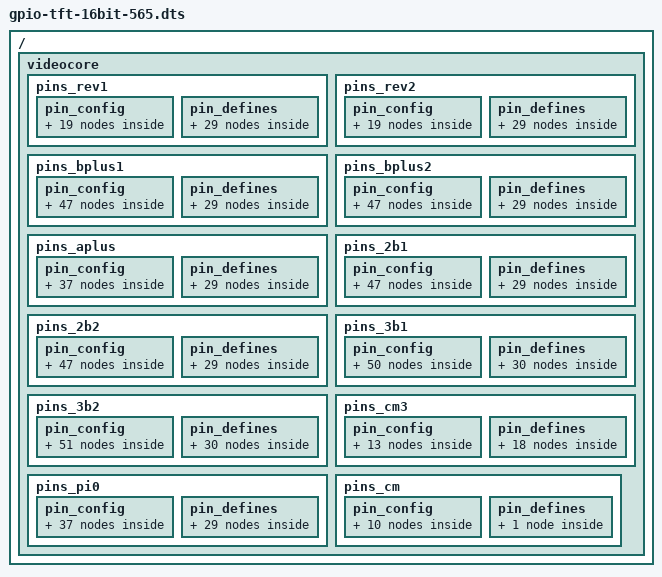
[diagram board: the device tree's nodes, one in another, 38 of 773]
/dts-v1/;

// Compile with the following script:
//#! /bin/bash
//echo "sudo dtc -I dts -O dtb -o /boot/dt-blob.bin gpio-tft-16bit-565.dts"
//sudo dtc -I dts -O dtb -o /boot/dt-blob.bin gpio-tft-16bit-565.dts


/ {
   videocore {
      pins_rev1 {
         pin_config {
            pin@default {
               polarity = "active_high";
               termination = "pull_down";
               startup_state = "inactive";
               function = "input";
            }; // pin
            pin@p2  { function = "i2c1";   termination = "pull_up"; }; // I2C 1 SDA
            pin@p3  { function = "i2c1";   termination = "pull_up"; }; // I2C 1 SCL
            pin@p5  { function = "output"; termination = "pull_down"; }; // CAM_LED
            pin@p6  { function = "output"; termination = "pull_down"; }; // LAN NRESET
            pin@p14 { function = "uart0";  termination = "no_pulling"; drive_strength_mA = < 8 >; }; // TX uart0
            pin@p15 { function = "uart0";  termination = "pull_up"; drive_strength_mA = < 8 >; }; // RX uart0
            pin@p16 { function = "output"; termination = "pull_up"; polarity="active_low"; }; // activity LED
            pin@p27 { function = "output"; termination = "no_pulling";    }; // Camera shutdown
            pin@p40 { function = "pwm";    termination = "no_pulling"; drive_strength_mA = < 16 >; }; // Left audio
            pin@p45 { function = "pwm";    termination = "no_pulling"; drive_strength_mA = < 16 >; }; // Right audio
            pin@p46 { function = "input";  termination = "no_pulling";    }; // Hotplug
            pin@p47 { function = "input";  termination = "no_pulling";    }; // SD_CARD_DETECT
            pin@p48 { function = "sdcard"; termination = "pull_up";    drive_strength_mA = < 8 >; }; // SD CLK
            pin@p49 { function = "sdcard"; termination = "pull_up";    drive_strength_mA = < 8 >; }; // SD CMD
            pin@p50 { function = "sdcard"; termination = "pull_up";    drive_strength_mA = < 8 >; }; // SD D0
            pin@p51 { function = "sdcard"; termination = "pull_up";    drive_strength_mA = < 8 >; }; // SD D1
            pin@p52 { function = "sdcard"; termination = "pull_up";    drive_strength_mA = < 8 >; }; // SD D2
            pin@p53 { function = "sdcard"; termination = "pull_up";    drive_strength_mA = < 8 >; }; // SD D3
         }; // pin_config

         pin_defines {
            pin_define@HDMI_CONTROL_ATTACHED {
               type = "internal";
               number = <46>;
            };
            pin_define@NUM_CAMERAS {
               type = "internal";
               number = <1>;
            };
            pin_define@CAMERA_0_UNICAM_PORT {
               type = "internal";
               number = <1>;
            };
            pin_define@CAMERA_0_I2C_PORT {
               type = "internal";
               number = <1>;
            };
            pin_define@CAMERA_0_SDA_PIN {
               type = "internal";
               number = <2>;
            };
            pin_define@CAMERA_0_SCL_PIN {
               type = "internal";
               number = <3>;
            };
            pin_define@CAMERA_0_SHUTDOWN {
               type = "internal";
               number = <27>;
            };
            pin_define@CAMERA_0_LED {
               type = "internal";
               number = <5>;
            };
            pin_define@FLASH_0_ENABLE {
               type = "absent";
            };
            pin_define@FLASH_0_INDICATOR {
               type = "absent";
            };
            pin_define@FLASH_1_ENABLE {
               type = "absent";
            };
            pin_define@FLASH_1_INDICATOR {
               type = "absent";
            };
            pin_define@POWER_LOW {
               type = "absent";
            };
            pin_define@LEDS_DISK_ACTIVITY {
               type = "internal";
               number = <16>;
            };
            pin_define@LAN_RUN {
               type = "internal";
               number = <6>;
            };
            pin_define@SMPS_SDA {
               type = "absent";
            };
            pin_define@SMPS_SCL {
               type = "absent";
            };
            pin_define@ETH_CLK {
               type = "absent";
            };
            pin_define@USB_LIMIT_1A2 {
               type = "absent";
            };
            pin_define@SIO_1V8_SEL {
               type = "absent";
            };
            pin_define@PWML {
               type = "internal";
               number = <40>;
            };
            pin_define@PWMR {
               type = "internal";
               number = <45>;
            };
            pin_define@SAFE_MODE {
               type = "internal";
               number = <1>;
            };
            pin_define@SD_CARD_DETECT {
               type = "internal";
               number = <47>;
            };
            pin_define@ID_SDA {
               type = "absent";
            };
            pin_define@ID_SCL {
               type = "absent";
            };
            pin_define@DISPLAY_I2C_PORT {
               type = "internal";
               number = <0>;
            };
            pin_define@DISPLAY_SDA {
               type = "internal";
               number = <0>;
            };
            pin_define@DISPLAY_SCL {
               type = "internal";
               number = <1>;
            };
         }; // pin_defines
      }; // pins_rev1

      pins_rev2 {
         pin_config {
            pin@default {
               polarity = "active_high";
               termination = "pull_down";
               startup_state = "inactive";
               function = "input";
            }; // pin
            pin@p0  { function = "i2c0";   termination = "pull_up"; }; // I2C 0 SDA
            pin@p1  { function = "i2c0";   termination = "pull_up"; }; // I2C 0 SCL
            pin@p5  { function = "output"; termination = "pull_down"; }; // CAM_LED
            pin@p6  { function = "output"; termination = "pull_down"; }; // LAN NRESET
            pin@p14 { function = "uart0";  termination = "no_pulling"; drive_strength_mA = < 8 >; }; // TX uart0
            pin@p15 { function = "uart0";  termination = "pull_up"; drive_strength_mA = < 8 >; }; // RX uart0
            pin@p16 { function = "output"; termination = "pull_up"; polarity = "active_low"; }; // activity LED
            pin@p21 { function = "output"; termination = "no_pulling";    }; // Camera shutdown
            pin@p40 { function = "pwm";    termination = "no_pulling"; drive_strength_mA = < 16 >; }; // Left audio
            pin@p45 { function = "pwm";    termination = "no_pulling"; drive_strength_mA = < 16 >; }; // Right audio
            pin@p46 { function = "input";  termination = "no_pulling";    }; // Hotplug
            pin@p47 { function = "input";  termination = "no_pulling";    }; // SD_CARD_DETECT
            pin@p48 { function = "sdcard"; termination = "pull_up";    drive_strength_mA = < 8 >; }; // SD CLK
            pin@p49 { function = "sdcard"; termination = "pull_up";    drive_strength_mA = < 8 >; }; // SD CMD
            pin@p50 { function = "sdcard"; termination = "pull_up";    drive_strength_mA = < 8 >; }; // SD D0
            pin@p51 { function = "sdcard"; termination = "pull_up";    drive_strength_mA = < 8 >; }; // SD D1
            pin@p52 { function = "sdcard"; termination = "pull_up";    drive_strength_mA = < 8 >; }; // SD D2
            pin@p53 { function = "sdcard"; termination = "pull_up";    drive_strength_mA = < 8 >; }; // SD D3
         }; // pin_config

         pin_defines {
            pin_define@HDMI_CONTROL_ATTACHED {
               type = "internal";
               number = <46>;
            };
            pin_define@NUM_CAMERAS {
               type = "internal";
               number = <1>;
            };
            pin_define@CAMERA_0_I2C_PORT {
               type = "internal";
               number = <0>;
            };
            pin_define@CAMERA_0_SDA_PIN {
               type = "internal";
               number = <0>;
            };
            pin_define@CAMERA_0_SCL_PIN {
               type = "internal";
               number = <1>;
            };
            pin_define@CAMERA_0_SHUTDOWN {
               type = "internal";
               number = <21>;
            };
            pin_define@CAMERA_0_UNICAM_PORT {
               type = "internal";
               number = <1>;
            };
            pin_define@CAMERA_0_LED {
               type = "internal";
               number = <5>;
            };
            pin_define@FLASH_0_ENABLE {
               type = "absent";
            };
            pin_define@FLASH_0_INDICATOR {
               type = "absent";
            };
            pin_define@FLASH_1_ENABLE {
               type = "absent";
            };
            pin_define@FLASH_1_INDICATOR {
               type = "absent";
            };
            pin_define@POWER_LOW {
               type = "absent";
            };
            pin_define@LEDS_DISK_ACTIVITY {
               type = "internal";
               number = <16>;
            };
            pin_define@LAN_RUN {
               type = "internal";
               number = <6>;
            };
            pin_define@SMPS_SDA {
               type = "absent";
            };
            pin_define@SMPS_SCL {
               type = "absent";
            };
            pin_define@ETH_CLK {
               type = "absent";
            };
            pin_define@USB_LIMIT_1A2 {
               type = "absent";
            };
            pin_define@SIO_1V8_SEL {
               type = "absent";
            };
            pin_define@PWML {
               type = "internal";
               number = <40>;
            };
            pin_define@PWMR {
               type = "internal";
               number = <45>;
            };
            pin_define@SAFE_MODE {
               type = "internal";
               number = <3>;
            };
            pin_define@SD_CARD_DETECT {
               type = "internal";
               number = <47>;
            };
            pin_define@ID_SDA {
               type = "absent";
            };
            pin_define@ID_SCL {
               type = "absent";
            };
            pin_define@DISPLAY_I2C_PORT {
               type = "internal";
               number = <1>;
            };
            pin_define@DISPLAY_SDA {
               type = "internal";
               number = <2>;
            };
            pin_define@DISPLAY_SCL {
               type = "internal";
               number = <3>;
            };
         }; // pin_defines
      }; // pins

      pins_bplus1 { // Pi 1 Model B+ rev 1.1
         pin_config {
            pin@default {
               polarity = "active_high";
               termination = "pull_down";
               startup_state = "inactive";
               function = "input";
            }; // pin
            // GPIOCONFIG: configure GPIO for 24-bit DPI interface
            pin@p0 { function = "dpi";  termination = "no_pulling"; drive_strength_mA = < 8 >; }; // CLK
            pin@p1 { function = "dpi";  termination = "no_pulling"; drive_strength_mA = < 8 >; }; // DEN
            pin@p2 { function = "dpi";  termination = "no_pulling"; drive_strength_mA = < 8 >; }; // VSYNC
            pin@p3 { function = "dpi";  termination = "no_pulling"; drive_strength_mA = < 8 >; }; // HSYNC
            pin@p4 { function = "dpi";  termination = "no_pulling"; drive_strength_mA = < 8 >; }; // B0
            pin@p5 { function = "dpi";  termination = "no_pulling"; drive_strength_mA = < 8 >; }; // B1
            pin@p6 { function = "dpi";  termination = "no_pulling"; drive_strength_mA = < 8 >; }; // B2
            pin@p7 { function = "dpi";  termination = "no_pulling"; drive_strength_mA = < 8 >; }; // B3
            pin@p8 { function = "dpi";  termination = "no_pulling"; drive_strength_mA = < 8 >; }; // B4
            pin@p9 { function = "dpi";  termination = "no_pulling"; drive_strength_mA = < 8 >; }; // B5
            pin@p10 { function = "dpi";  termination = "no_pulling"; drive_strength_mA = < 8 >; }; // B6
            pin@p11 { function = "dpi";  termination = "no_pulling"; drive_strength_mA = < 8 >; }; // B7
            pin@p12 { function = "dpi";  termination = "no_pulling"; drive_strength_mA = < 8 >; }; // G0
            pin@p13 { function = "dpi";  termination = "no_pulling"; drive_strength_mA = < 8 >; }; // G1
            pin@p14 { function = "dpi";  termination = "no_pulling"; drive_strength_mA = < 8 >; }; // G2
            pin@p15 { function = "dpi";  termination = "no_pulling"; drive_strength_mA = < 8 >; }; // G3
            pin@p16 { function = "dpi";  termination = "no_pulling"; drive_strength_mA = < 8 >; }; // G4
            pin@p17 { function = "dpi";  termination = "no_pulling"; drive_strength_mA = < 8 >; }; // G5
            pin@p18 { function = "dpi";  termination = "no_pulling"; drive_strength_mA = < 8 >; }; // G6
            pin@p19 { function = "dpi";  termination = "no_pulling"; drive_strength_mA = < 8 >; }; // G7
            pin@p20 { function = "dpi";  termination = "no_pulling"; drive_strength_mA = < 8 >; }; // R0
            pin@p21 { function = "dpi";  termination = "no_pulling"; drive_strength_mA = < 8 >; }; // R1
            pin@p22 { function = "dpi";  termination = "no_pulling"; drive_strength_mA = < 8 >; }; // R2
            pin@p23 { function = "dpi";  termination = "no_pulling"; drive_strength_mA = < 8 >; }; // R3
            pin@p24 { function = "dpi";  termination = "no_pulling"; drive_strength_mA = < 8 >; }; // R4
            pin@p25 { function = "dpi";  termination = "no_pulling"; drive_strength_mA = < 8 >; }; // R5
            pin@p26 { function = "dpi";  termination = "no_pulling"; drive_strength_mA = < 8 >; }; // R6
            pin@p27 { function = "dpi";  termination = "no_pulling"; drive_strength_mA = < 8 >; }; // R7
            // end GPIOCONFIG; leave the rest untouched!

	    //pin@p14 { function = "uart0";  termination = "no_pulling"; drive_strength_mA = < 8 >; }; // TX uart0
            //pin@p15 { function = "uart0";  termination = "pull_up"; drive_strength_mA = < 8 >; }; // RX uart0
            pin@p28 { function = "i2c0";   termination = "pull_up";    }; // I2C 0 SDA
            pin@p29 { function = "i2c0";   termination = "pull_up";    }; // I2C 0 SCL
            pin@p31 { function = "input";  termination = "no_pulling"; polarity = "active_low"; }; // Power low
            pin@p32 { function = "output"; termination = "pull_down"; }; // Camera LED
            pin@p35 { function = "output"; termination = "pull_down"; }; // LAN_RUN
            pin@p38 { function = "output"; termination = "no_pulling";    }; // USB current limit (0=600mA, 1=1200mA)
            pin@p40 { function = "pwm";    termination = "no_pulling"; drive_strength_mA = < 16 >; }; // Right audio
            pin@p41 { function = "output"; termination = "no_pulling";    }; // Camera shutdown
            pin@p44 { function = "gp_clk"; termination = "pull_down"; }; // ETH_CLK - Ethernet 25MHz output
            pin@p45 { function = "pwm";    termination = "no_pulling"; drive_strength_mA = < 16 >; }; // Left audio
            pin@p46 { function = "input";  termination = "no_pulling"; polarity = "active_low"; }; // Hotplug
            pin@p47 { function = "output"; termination = "pull_down"; }; // activity LED
            pin@p48 { function = "sdcard"; termination = "pull_up";    drive_strength_mA = < 8 >; }; // SD CLK
            pin@p49 { function = "sdcard"; termination = "pull_up";    drive_strength_mA = < 8 >; }; // SD CMD
            pin@p50 { function = "sdcard"; termination = "pull_up";    drive_strength_mA = < 8 >; }; // SD D0
            pin@p51 { function = "sdcard"; termination = "pull_up";    drive_strength_mA = < 8 >; }; // SD D1
            pin@p52 { function = "sdcard"; termination = "pull_up";    drive_strength_mA = < 8 >; }; // SD D2
            pin@p53 { function = "sdcard"; termination = "pull_up";    drive_strength_mA = < 8 >; }; // SD D3
         }; // pin_config

         pin_defines {
            pin_define@HDMI_CONTROL_ATTACHED {
               type = "internal";
               number = <46>;
            };
            pin_define@NUM_CAMERAS {
               type = "internal";
               number = <1>;
            };
            pin_define@CAMERA_0_I2C_PORT {
               type = "internal";
               number = <0>;
            };
            pin_define@CAMERA_0_SDA_PIN {
               type = "internal";
               number = <28>;
            };
            pin_define@CAMERA_0_SCL_PIN {
               type = "internal";
               number = <29>;
            };
            pin_define@CAMERA_0_SHUTDOWN {
               type = "internal";
               number = <41>;
            };
            pin_define@CAMERA_0_UNICAM_PORT {
               type = "internal";
               number = <1>;
            };
            pin_define@CAMERA_0_LED {
               type = "internal";
               number = <32>;
            };
            pin_define@FLASH_0_ENABLE {
               type = "absent";
            };
            pin_define@FLASH_0_INDICATOR {
               type = "absent";
            };
            pin_define@FLASH_1_ENABLE {
               type = "absent";
            };
            pin_define@FLASH_1_INDICATOR {
               type = "absent";
            };
            pin_define@POWER_LOW {
               type = "internal";
               number = <31>;
            };
            pin_define@LEDS_DISK_ACTIVITY {
               type = "internal";
               number = <47>;
            };
            pin_define@LAN_RUN {
               type = "internal";
               number = <35>;
            };
            pin_define@SMPS_SDA {
               type = "absent";
            };
            pin_define@SMPS_SCL {
               type = "absent";
            };
            pin_define@ETH_CLK {
               type = "internal";
               number = <44>;
            };
            pin_define@USB_LIMIT_1A2 {
               type = "absent";
            };
            pin_define@SIO_1V8_SEL {
               type = "internal";
               number = <38>;
            };
            pin_define@PWML {
               type = "internal";
               number = <45>;
            };
            pin_define@PWMR {
               type = "internal";
               number = <40>;
            };
            pin_define@SAFE_MODE {
               type = "internal";
               number = <3>;
            };
            pin_define@SD_CARD_DETECT {
               type = "absent";
            };
            pin_define@ID_SDA {
               type = "internal";
               number = <0>;
            };
            pin_define@ID_SCL {
               type = "internal";
               number = <1>;
            };
            pin_define@DISPLAY_I2C_PORT {
               type = "internal";
               number = <0>;
            };
            pin_define@DISPLAY_SDA {
               type = "internal";
               number = <28>;
            };
            pin_define@DISPLAY_SCL {
               type = "internal";
               number = <29>;
            };
         }; // pin_defines
      }; // pins

      pins_bplus2 { // Pi 1 Model B+ rev 1.2
         pin_config {
            pin@default {
               polarity = "active_high";
               termination = "pull_down";
               startup_state = "inactive";
               function = "input";
            }; // pin
            // GPIOCONFIG: configure GPIO for 24-bit DPI interface
            pin@p0 { function = "dpi";  termination = "no_pulling"; drive_strength_mA = < 8 >; };  // CLK
            pin@p1 { function = "dpi";  termination = "no_pulling"; drive_strength_mA = < 8 >; };  // DEN
            pin@p2 { function = "dpi";  termination = "no_pulling"; drive_strength_mA = < 8 >; };  // VSYNC
            pin@p3 { function = "dpi";  termination = "no_pulling"; drive_strength_mA = < 8 >; };  // HSYNC
            pin@p4 { function = "dpi";  termination = "no_pulling"; drive_strength_mA = < 8 >; };  // B0
            pin@p5 { function = "dpi";  termination = "no_pulling"; drive_strength_mA = < 8 >; };  // B1
            pin@p6 { function = "dpi";  termination = "no_pulling"; drive_strength_mA = < 8 >; };  // B2
            pin@p7 { function = "dpi";  termination = "no_pulling"; drive_strength_mA = < 8 >; };  // B3
            pin@p8 { function = "dpi";  termination = "no_pulling"; drive_strength_mA = < 8 >; };  // B4
            pin@p9 { function = "dpi";  termination = "no_pulling"; drive_strength_mA = < 8 >; };  // B5
            pin@p10 { function = "dpi";  termination = "no_pulling"; drive_strength_mA = < 8 >; }; // B6
            pin@p11 { function = "dpi";  termination = "no_pulling"; drive_strength_mA = < 8 >; }; // B7
            pin@p12 { function = "dpi";  termination = "no_pulling"; drive_strength_mA = < 8 >; }; // G0
            pin@p13 { function = "dpi";  termination = "no_pulling"; drive_strength_mA = < 8 >; }; // G1
            pin@p14 { function = "dpi";  termination = "no_pulling"; drive_strength_mA = < 8 >; }; // G2
            pin@p15 { function = "dpi";  termination = "no_pulling"; drive_strength_mA = < 8 >; }; // G3
            pin@p16 { function = "dpi";  termination = "no_pulling"; drive_strength_mA = < 8 >; }; // G4
            pin@p17 { function = "dpi";  termination = "no_pulling"; drive_strength_mA = < 8 >; }; // G5
            pin@p18 { function = "dpi";  termination = "no_pulling"; drive_strength_mA = < 8 >; }; // G6
            pin@p19 { function = "dpi";  termination = "no_pulling"; drive_strength_mA = < 8 >; }; // G7
            pin@p20 { function = "dpi";  termination = "no_pulling"; drive_strength_mA = < 8 >; }; // R0
            pin@p21 { function = "dpi";  termination = "no_pulling"; drive_strength_mA = < 8 >; }; // R1
            pin@p22 { function = "dpi";  termination = "no_pulling"; drive_strength_mA = < 8 >; }; // R2
            pin@p23 { function = "dpi";  termination = "no_pulling"; drive_strength_mA = < 8 >; }; // R3
            pin@p24 { function = "dpi";  termination = "no_pulling"; drive_strength_mA = < 8 >; }; // R4
            pin@p25 { function = "dpi";  termination = "no_pulling"; drive_strength_mA = < 8 >; }; // R5
            pin@p26 { function = "dpi";  termination = "no_pulling"; drive_strength_mA = < 8 >; }; // R6
            pin@p27 { function = "dpi";  termination = "no_pulling"; drive_strength_mA = < 8 >; }; // R7
            // end GPIOCONFIG; leave the rest untouched!

	    //pin@p14 { function = "uart0";  termination = "no_pulling"; drive_strength_mA = < 8 >; }; // TX uart0
            //pin@p15 { function = "uart0";  termination = "pull_up"; drive_strength_mA = < 8 >; }; // RX uart0
            pin@p28 { function = "i2c0";   termination = "pull_up";    }; // I2C 0 SDA
            pin@p29 { function = "i2c0";   termination = "pull_up";    }; // I2C 0 SCL
            pin@p31 { function = "output"; termination = "pull_down"; }; // LAN_RUN
            pin@p32 { function = "output"; termination = "pull_down"; }; // Camera LED
            pin@p35 { function = "input";  termination = "no_pulling"; polarity = "active_low"; }; // Power low
            pin@p38 { function = "output"; termination = "no_pulling";    }; // USB current limit (0=600mA, 1=1200mA)
            pin@p40 { function = "pwm";    termination = "no_pulling"; drive_strength_mA = < 16 >; }; // Right audio
            pin@p41 { function = "output"; termination = "no_pulling";    }; // Camera shutdown
            pin@p44 { function = "gp_clk"; termination = "pull_down"; }; // ETH_CLK - Ethernet 25MHz output
            pin@p45 { function = "pwm";    termination = "no_pulling"; drive_strength_mA = < 16 >; }; // Left audio
            pin@p46 { function = "input";  termination = "no_pulling"; polarity = "active_low"; }; // Hotplug
            pin@p47 { function = "output"; termination = "pull_down"; }; // activity LED
            pin@p48 { function = "sdcard"; termination = "pull_up";    drive_strength_mA = < 8 >; }; // SD CLK
            pin@p49 { function = "sdcard"; termination = "pull_up";    drive_strength_mA = < 8 >; }; // SD CMD
            pin@p50 { function = "sdcard"; termination = "pull_up";    drive_strength_mA = < 8 >; }; // SD D0
            pin@p51 { function = "sdcard"; termination = "pull_up";    drive_strength_mA = < 8 >; }; // SD D1
            pin@p52 { function = "sdcard"; termination = "pull_up";    drive_strength_mA = < 8 >; }; // SD D2
            pin@p53 { function = "sdcard"; termination = "pull_up";    drive_strength_mA = < 8 >; }; // SD D3
         }; // pin_config

         pin_defines {
            pin_define@HDMI_CONTROL_ATTACHED {
               type = "internal";
               number = <46>;
            };
            pin_define@NUM_CAMERAS {
               type = "internal";
               number = <1>;
            };
            pin_define@CAMERA_0_I2C_PORT {
               type = "internal";
               number = <0>;
            };
            pin_define@CAMERA_0_SDA_PIN {
               type = "internal";
               number = <28>;
            };
            pin_define@CAMERA_0_SCL_PIN {
               type = "internal";
               number = <29>;
            };
            pin_define@CAMERA_0_SHUTDOWN {
               type = "internal";
               number = <41>;
            };
            pin_define@CAMERA_0_UNICAM_PORT {
               type = "internal";
               number = <1>;
            };
            pin_define@CAMERA_0_LED {
               type = "internal";
               number = <32>;
            };
            pin_define@FLASH_0_ENABLE {
               type = "absent";
            };
            pin_define@FLASH_0_INDICATOR {
               type = "absent";
            };
            pin_define@FLASH_1_ENABLE {
               type = "absent";
            };
            pin_define@FLASH_1_INDICATOR {
               type = "absent";
            };
            pin_define@POWER_LOW {
               type = "internal";
               number = <35>;
            };
            pin_define@LEDS_DISK_ACTIVITY {
               type = "internal";
               number = <47>;
            };
            pin_define@LAN_RUN {
               type = "internal";
               number = <31>;
            };
            pin_define@SMPS_SDA {
               type = "absent";
            };
            pin_define@SMPS_SCL {
               type = "absent";
            };
            pin_define@ETH_CLK {
               type = "internal";
               number = <44>;
            };
            pin_define@USB_LIMIT_1A2 {
               type = "internal";
               number = <38>;
            };
            pin_define@SIO_1V8_SEL {
               type = "absent";
            };
            pin_define@PWML {
               type = "internal";
               number = <45>;
            };
            pin_define@PWMR {
               type = "internal";
               number = <40>;
            };
            pin_define@SAFE_MODE {
               type = "internal";
               number = <3>;
            };
            pin_define@SD_CARD_DETECT {
               type = "absent";
            };
            pin_define@ID_SDA {
               type = "internal";
               number = <0>;
            };
            pin_define@ID_SCL {
               type = "internal";
               number = <1>;
            };
            pin_define@DISPLAY_I2C_PORT {
               type = "internal";
               number = <0>;
            };
            pin_define@DISPLAY_SDA {
               type = "internal";
               number = <28>;
            };
            pin_define@DISPLAY_SCL {
               type = "internal";
               number = <29>;
            };
         }; // pin_defines
      }; // pins

      pins_aplus {
         pin_config {
            pin@default {
               polarity = "active_high";
               termination = "pull_down";
               startup_state = "inactive";
               function = "input";
            }; // pin
            // GPIOCONFIG: configure GPIO for 24-bit DPI interface
            pin@p0 { function = "dpi";  termination = "no_pulling"; drive_strength_mA = < 8 >; }; // CLK
            pin@p1 { function = "dpi";  termination = "no_pulling"; drive_strength_mA = < 8 >; }; // DEN
            pin@p2 { function = "dpi";  termination = "no_pulling"; drive_strength_mA = < 8 >; }; // VSYNC
            pin@p3 { function = "dpi";  termination = "no_pulling"; drive_strength_mA = < 8 >; }; // HSYNC
            pin@p4 { function = "dpi";  termination = "no_pulling"; drive_strength_mA = < 8 >; }; // B0
            pin@p5 { function = "dpi";  termination = "no_pulling"; drive_strength_mA = < 8 >; }; // B1
            pin@p6 { function = "dpi";  termination = "no_pulling"; drive_strength_mA = < 8 >; }; // B2
            pin@p7 { function = "dpi";  termination = "no_pulling"; drive_strength_mA = < 8 >; }; // B3
            pin@p8 { function = "dpi";  termination = "no_pulling"; drive_strength_mA = < 8 >; }; // B4
            pin@p9 { function = "dpi";  termination = "no_pulling"; drive_strength_mA = < 8 >; }; // B5
            pin@p10 { function = "dpi";  termination = "no_pulling"; drive_strength_mA = < 8 >; }; // B6
            pin@p11 { function = "dpi";  termination = "no_pulling"; drive_strength_mA = < 8 >; }; // B7
            pin@p12 { function = "dpi";  termination = "no_pulling"; drive_strength_mA = < 8 >; }; // G0
            pin@p13 { function = "dpi";  termination = "no_pulling"; drive_strength_mA = < 8 >; }; // G1
            pin@p14 { function = "dpi";  termination = "no_pulling"; drive_strength_mA = < 8 >; }; // G2
            pin@p15 { function = "dpi";  termination = "no_pulling"; drive_strength_mA = < 8 >; }; // G3
            pin@p16 { function = "dpi";  termination = "no_pulling"; drive_strength_mA = < 8 >; }; // G4
            pin@p17 { function = "dpi";  termination = "no_pulling"; drive_strength_mA = < 8 >; }; // G5
            pin@p18 { function = "dpi";  termination = "no_pulling"; drive_strength_mA = < 8 >; }; // G6
            pin@p19 { function = "dpi";  termination = "no_pulling"; drive_strength_mA = < 8 >; }; // G7

            // end GPIOCONFIG; leave the rest untouched!

	    //pin@p14 { function = "uart0";  termination = "no_pulling"; drive_strength_mA = < 8 >; }; // TX uart0
            //pin@p15 { function = "uart0";  termination = "pull_up"; drive_strength_mA = < 8 >; }; // RX uart0
            pin@p28 { function = "i2c0";   termination = "pull_up";    }; // I2C 0 SDA
            pin@p29 { function = "i2c0";   termination = "pull_up";    }; // I2C 0 SCL
            pin@p32 { function = "output"; termination = "pull_down"; }; // Camera LED
            pin@p35 { function = "input";  termination = "no_pulling"; polarity = "active_low"; }; // Power low
            pin@p38 { function = "output"; termination = "no_pulling";    }; // USB current limit (0=600mA, 1=1200mA)
            pin@p40 { function = "pwm";    termination = "no_pulling"; drive_strength_mA = < 16 >; }; // Right audio
            pin@p41 { function = "output"; termination = "no_pulling";    }; // Camera shutdown
            pin@p45 { function = "pwm";    termination = "no_pulling"; drive_strength_mA = < 16 >; }; // Left audio
            pin@p46 { function = "input";  termination = "no_pulling"; polarity = "active_low"; }; // Hotplug
            pin@p47 { function = "output"; termination = "pull_down"; }; // activity LED
            pin@p48 { function = "sdcard"; termination = "pull_up";    drive_strength_mA = < 8 >; }; // SD CLK
            pin@p49 { function = "sdcard"; termination = "pull_up";    drive_strength_mA = < 8 >; }; // SD CMD
            pin@p50 { function = "sdcard"; termination = "pull_up";    drive_strength_mA = < 8 >; }; // SD D0
            pin@p51 { function = "sdcard"; termination = "pull_up";    drive_strength_mA = < 8 >; }; // SD D1
            pin@p52 { function = "sdcard"; termination = "pull_up";    drive_strength_mA = < 8 >; }; // SD D2
            pin@p53 { function = "sdcard"; termination = "pull_up";    drive_strength_mA = < 8 >; }; // SD D3
         }; // pin_config

         pin_defines {
            pin_define@HDMI_CONTROL_ATTACHED {
               type = "internal";
               number = <46>;
            };
            pin_define@NUM_CAMERAS {
               type = "internal";
               number = <1>;
            };
            pin_define@CAMERA_0_I2C_PORT {
               type = "internal";
               number = <0>;
            };
            pin_define@CAMERA_0_SDA_PIN {
               type = "internal";
               number = <28>;
            };
            pin_define@CAMERA_0_SCL_PIN {
               type = "internal";
               number = <29>;
            };
            pin_define@CAMERA_0_SHUTDOWN {
               type = "internal";
               number = <41>;
            };
            pin_define@CAMERA_0_UNICAM_PORT {
               type = "internal";
               number = <1>;
            };
            pin_define@CAMERA_0_LED {
               type = "internal";
               number = <32>;
            };
            pin_define@FLASH_0_ENABLE {
               type = "absent";
            };
            pin_define@FLASH_0_INDICATOR {
               type = "absent";
            };
            pin_define@FLASH_1_ENABLE {
               type = "absent";
            };
            pin_define@FLASH_1_INDICATOR {
               type = "absent";
            };
            pin_define@POWER_LOW {
               type = "internal";
               number = <35>;
            };
            pin_define@LEDS_DISK_ACTIVITY {
               type = "internal";
               number = <47>;
            };
            pin_define@LAN_RUN {
               type = "absent";
            };
            pin_define@SMPS_SDA {
               type = "absent";
            };
            pin_define@SMPS_SCL {
               type = "absent";
            };
            pin_define@ETH_CLK {
               type = "absent";
            };
            pin_define@USB_LIMIT_1A2 {
               type = "internal";
               number = <38>;
            };
            pin_define@SIO_1V8_SEL {
               type = "absent";
            };
            pin_define@PWML {
               type = "internal";
               number = <45>;
            };
            pin_define@PWMR {
               type = "internal";
               number = <40>;
            };
            pin_define@SAFE_MODE {
               type = "internal";
               number = <3>;
            };
            pin_define@SD_CARD_DETECT {
               type = "absent";
            };
            pin_define@ID_SDA {
               type = "internal";
               number = <0>;
            };
            pin_define@ID_SCL {
               type = "internal";
               number = <1>;
            };
            pin_define@DISPLAY_I2C_PORT {
               type = "internal";
               number = <0>;
            };
            pin_define@DISPLAY_SDA {
               type = "internal";
               number = <28>;
            };
            pin_define@DISPLAY_SCL {
               type = "internal";
               number = <29>;
            };
         }; // pin_defines
      }; // pins

      pins_2b1 { // Pi 2 Model B rev 1.0
         pin_config {
            pin@default {
               polarity = "active_high";
               termination = "pull_down";
               startup_state = "inactive";
               function = "input";
            }; // pin
            // GPIOCONFIG: configure GPIO for 24-bit DPI interface
            pin@p0 { function = "dpi";  termination = "no_pulling"; drive_strength_mA = < 8 >; }; // CLK
            pin@p1 { function = "dpi";  termination = "no_pulling"; drive_strength_mA = < 8 >; }; // DEN
            pin@p2 { function = "dpi";  termination = "no_pulling"; drive_strength_mA = < 8 >; }; // VSYNC
            pin@p3 { function = "dpi";  termination = "no_pulling"; drive_strength_mA = < 8 >; }; // HSYNC
            pin@p4 { function = "dpi";  termination = "no_pulling"; drive_strength_mA = < 8 >; }; // B0
            pin@p5 { function = "dpi";  termination = "no_pulling"; drive_strength_mA = < 8 >; }; // B1
            pin@p6 { function = "dpi";  termination = "no_pulling"; drive_strength_mA = < 8 >; }; // B2
            pin@p7 { function = "dpi";  termination = "no_pulling"; drive_strength_mA = < 8 >; }; // B3
            pin@p8 { function = "dpi";  termination = "no_pulling"; drive_strength_mA = < 8 >; }; // B4
            pin@p9 { function = "dpi";  termination = "no_pulling"; drive_strength_mA = < 8 >; }; // B5
            pin@p10 { function = "dpi";  termination = "no_pulling"; drive_strength_mA = < 8 >; }; // B6
            pin@p11 { function = "dpi";  termination = "no_pulling"; drive_strength_mA = < 8 >; }; // B7
            pin@p12 { function = "dpi";  termination = "no_pulling"; drive_strength_mA = < 8 >; }; // G0
            pin@p13 { function = "dpi";  termination = "no_pulling"; drive_strength_mA = < 8 >; }; // G1
            pin@p14 { function = "dpi";  termination = "no_pulling"; drive_strength_mA = < 8 >; }; // G2
            pin@p15 { function = "dpi";  termination = "no_pulling"; drive_strength_mA = < 8 >; }; // G3
            pin@p16 { function = "dpi";  termination = "no_pulling"; drive_strength_mA = < 8 >; }; // G4
            pin@p17 { function = "dpi";  termination = "no_pulling"; drive_strength_mA = < 8 >; }; // G5
            pin@p18 { function = "dpi";  termination = "no_pulling"; drive_strength_mA = < 8 >; }; // G6
            pin@p19 { function = "dpi";  termination = "no_pulling"; drive_strength_mA = < 8 >; }; // G7
            pin@p20 { function = "dpi";  termination = "no_pulling"; drive_strength_mA = < 8 >; }; // R0
            pin@p21 { function = "dpi";  termination = "no_pulling"; drive_strength_mA = < 8 >; }; // R1
            pin@p22 { function = "dpi";  termination = "no_pulling"; drive_strength_mA = < 8 >; }; // R2
            pin@p23 { function = "dpi";  termination = "no_pulling"; drive_strength_mA = < 8 >; }; // R3
            pin@p24 { function = "dpi";  termination = "no_pulling"; drive_strength_mA = < 8 >; }; // R4
            pin@p25 { function = "dpi";  termination = "no_pulling"; drive_strength_mA = < 8 >; }; // R5
            pin@p26 { function = "dpi";  termination = "no_pulling"; drive_strength_mA = < 8 >; }; // R6
            pin@p27 { function = "dpi";  termination = "no_pulling"; drive_strength_mA = < 8 >; }; // R7
            // end GPIOCONFIG; leave the rest untouched!

	    //pin@p14 { function = "uart0";  termination = "no_pulling"; drive_strength_mA = < 8 >; }; // TX uart0
            //pin@p15 { function = "uart0";  termination = "pull_up"; drive_strength_mA = < 8 >; }; // RX uart0
            pin@p28 { function = "i2c0";   termination = "pull_up";    }; // I2C 0 SDA / SMPS_SDA
            pin@p29 { function = "i2c0";   termination = "pull_up";    }; // I2C 0 SCL / SMPS_SCL
            pin@p31 { function = "output"; termination = "pull_down"; }; // LAN_RUN
            pin@p32 { function = "output"; termination = "pull_down"; }; // Camera LED
            pin@p35 { function = "input";  termination = "no_pulling"; polarity = "active_low"; }; // Power low
            pin@p38 { function = "output"; termination = "no_pulling";    }; // USB current limit (0=600mA, 1=1200mA)
            pin@p40 { function = "pwm";    termination = "no_pulling"; drive_strength_mA = < 16 >; }; // Right audio
            pin@p41 { function = "output"; termination = "no_pulling";    }; // Camera shutdown
            pin@p44 { function = "gp_clk"; termination = "pull_down"; }; // ETH_CLK - Ethernet 25MHz output
            pin@p45 { function = "pwm";    termination = "no_pulling"; drive_strength_mA = < 16 >; }; // Left audio
            pin@p46 { function = "input";  termination = "no_pulling"; polarity = "active_low"; }; // Hotplug
            pin@p47 { function = "output"; termination = "pull_down"; }; // activity LED
            pin@p48 { function = "sdcard"; termination = "pull_up";    drive_strength_mA = < 8 >; }; // SD CLK
            pin@p49 { function = "sdcard"; termination = "pull_up";    drive_strength_mA = < 8 >; }; // SD CMD
            pin@p50 { function = "sdcard"; termination = "pull_up";    drive_strength_mA = < 8 >; }; // SD D0
            pin@p51 { function = "sdcard"; termination = "pull_up";    drive_strength_mA = < 8 >; }; // SD D1
            pin@p52 { function = "sdcard"; termination = "pull_up";    drive_strength_mA = < 8 >; }; // SD D2
            pin@p53 { function = "sdcard"; termination = "pull_up";    drive_strength_mA = < 8 >; }; // SD D3
         }; // pin_config

         pin_defines {
            pin_define@HDMI_CONTROL_ATTACHED {
               type = "internal";
               number = <46>;
            };
            pin_define@NUM_CAMERAS {
               type = "internal";
               number = <1>;
            };
            pin_define@CAMERA_0_I2C_PORT {
               type = "internal";
               number = <0>;
            };
            pin_define@CAMERA_0_SDA_PIN {
               type = "internal";
               number = <28>;
            };
            pin_define@CAMERA_0_SCL_PIN {
               type = "internal";
               number = <29>;
            };
            pin_define@CAMERA_0_SHUTDOWN {
               type = "internal";
               number = <41>;
            };
            pin_define@CAMERA_0_UNICAM_PORT {
               type = "internal";
               number = <1>;
            };
            pin_define@CAMERA_0_LED {
               type = "internal";
               number = <32>;
            };
            pin_define@FLASH_0_ENABLE {
               type = "absent";
            };
            pin_define@FLASH_0_INDICATOR {
               type = "absent";
            };
            pin_define@FLASH_1_ENABLE {
               type = "absent";
            };
            pin_define@FLASH_1_INDICATOR {
               type = "absent";
            };
            pin_define@POWER_LOW {
               type = "internal";
               number = <35>;
            };
            pin_define@LEDS_DISK_ACTIVITY {
               type = "internal";
               number = <47>;
            };
            pin_define@LAN_RUN {
               type = "internal";
               number = <31>;
            };
            pin_define@SMPS_SDA {
               type = "internal";
               number = <28>;
            };
            pin_define@SMPS_SCL {
               type = "internal";
               number = <29>;
            };
            pin_define@ETH_CLK {
               type = "internal";
               number = <44>;
            };
            pin_define@USB_LIMIT_1A2 {
               type = "internal";
               number = <38>;
            };
            pin_define@SIO_1V8_SEL {
               type = "absent";
            };
            pin_define@PWML {
               type = "internal";
               number = <45>;
            };
            pin_define@PWMR {
               type = "internal";
               number = <40>;
            };
            pin_define@SAFE_MODE {
               type = "internal";
               number = <3>;
            };
            pin_define@SD_CARD_DETECT {
               type = "absent";
            };
            pin_define@ID_SDA {
               type = "internal";
               number = <0>;
            };
            pin_define@ID_SCL {
               type = "internal";
               number = <1>;
            };
            pin_define@DISPLAY_I2C_PORT {
               type = "internal";
               number = <0>;
            };
            pin_define@DISPLAY_SDA {
               type = "internal";
               number = <28>;
            };
            pin_define@DISPLAY_SCL {
               type = "internal";
               number = <29>;
            };
         }; // pin_defines
      }; // pins

      pins_2b2 { // Pi 2 Model B rev 1.1
         pin_config {
            pin@default {
               polarity = "active_high";
               termination = "pull_down";
               startup_state = "inactive";
               function = "input";
            }; // pin
            // GPIOCONFIG: configure GPIO for 24-bit DPI interface
            pin@p0 { function = "dpi";  termination = "no_pulling"; drive_strength_mA = < 8 >; }; // CLK
            pin@p1 { function = "dpi";  termination = "no_pulling"; drive_strength_mA = < 8 >; }; // DEN
            pin@p2 { function = "dpi";  termination = "no_pulling"; drive_strength_mA = < 8 >; }; // VSYNC
            pin@p3 { function = "dpi";  termination = "no_pulling"; drive_strength_mA = < 8 >; }; // HSYNC
            pin@p4 { function = "dpi";  termination = "no_pulling"; drive_strength_mA = < 8 >; }; // B0
            pin@p5 { function = "dpi";  termination = "no_pulling"; drive_strength_mA = < 8 >; }; // B1
            pin@p6 { function = "dpi";  termination = "no_pulling"; drive_strength_mA = < 8 >; }; // B2
            pin@p7 { function = "dpi";  termination = "no_pulling"; drive_strength_mA = < 8 >; }; // B3
            pin@p8 { function = "dpi";  termination = "no_pulling"; drive_strength_mA = < 8 >; }; // B4
            pin@p9 { function = "dpi";  termination = "no_pulling"; drive_strength_mA = < 8 >; }; // B5
            pin@p10 { function = "dpi";  termination = "no_pulling"; drive_strength_mA = < 8 >; }; // B6
            pin@p11 { function = "dpi";  termination = "no_pulling"; drive_strength_mA = < 8 >; }; // B7
            pin@p12 { function = "dpi";  termination = "no_pulling"; drive_strength_mA = < 8 >; }; // G0
            pin@p13 { function = "dpi";  termination = "no_pulling"; drive_strength_mA = < 8 >; }; // G1
            pin@p14 { function = "dpi";  termination = "no_pulling"; drive_strength_mA = < 8 >; }; // G2
            pin@p15 { function = "dpi";  termination = "no_pulling"; drive_strength_mA = < 8 >; }; // G3
            pin@p16 { function = "dpi";  termination = "no_pulling"; drive_strength_mA = < 8 >; }; // G4
            pin@p17 { function = "dpi";  termination = "no_pulling"; drive_strength_mA = < 8 >; }; // G5
            pin@p18 { function = "dpi";  termination = "no_pulling"; drive_strength_mA = < 8 >; }; // G6
            pin@p19 { function = "dpi";  termination = "no_pulling"; drive_strength_mA = < 8 >; }; // G7
            pin@p20 { function = "dpi";  termination = "no_pulling"; drive_strength_mA = < 8 >; }; // R0
            pin@p21 { function = "dpi";  termination = "no_pulling"; drive_strength_mA = < 8 >; }; // R1
            pin@p22 { function = "dpi";  termination = "no_pulling"; drive_strength_mA = < 8 >; }; // R2
            pin@p23 { function = "dpi";  termination = "no_pulling"; drive_strength_mA = < 8 >; }; // R3
            pin@p24 { function = "dpi";  termination = "no_pulling"; drive_strength_mA = < 8 >; }; // R4
            pin@p25 { function = "dpi";  termination = "no_pulling"; drive_strength_mA = < 8 >; }; // R5
            pin@p26 { function = "dpi";  termination = "no_pulling"; drive_strength_mA = < 8 >; }; // R6
            pin@p27 { function = "dpi";  termination = "no_pulling"; drive_strength_mA = < 8 >; }; // R7
            // end GPIOCONFIG; leave the rest untouched!

	    //pin@p14 { function = "uart0";  termination = "no_pulling"; drive_strength_mA = < 8 >; }; // TX uart0
            //pin@p15 { function = "uart0";  termination = "pull_up"; drive_strength_mA = < 8 >; }; // RX uart0

            // The firmware changes I2C pin functions on the fly, returning them to inputs when done. But pins 28&29 are
            // not used on a 1.1 Pi2, so the I2C0 function ends up multiply mapped (bad). therefore don't statically map.
            // pin@p28 { function = "i2c0";   termination = "pull_up";    }; // I2C 0 SDA
            // pin@p29 { function = "i2c0";   termination = "pull_up";    }; // I2C 0 SCL
            pin@p31 { function = "output"; termination = "pull_down"; }; // LAN_RUN
            pin@p32 { function = "output"; termination = "pull_down"; }; // Camera LED
            pin@p35 { function = "input";  termination = "no_pulling"; polarity = "active_low"; }; // Power low
            pin@p38 { function = "output"; termination = "no_pulling";    }; // USB current limit (0=600mA, 1=1200mA)
            pin@p40 { function = "pwm";    termination = "no_pulling"; drive_strength_mA = < 16 >; }; // Right audio
            pin@p41 { function = "output"; termination = "no_pulling";    }; // Camera shutdown
            // Communicate with the SMPS by "bit-bashing" the I2C protocol on GPIOs 42 and 43
            pin@p42 { function = "output"; termination = "pull_up";    }; // SMPS_SCL
            pin@p43 { function = "input";  termination = "no_pulling";    }; // SMPS_SDA
            pin@p44 { function = "gp_clk"; termination = "pull_down"; }; // ETH_CLK - Ethernet 25MHz output
            pin@p45 { function = "pwm";    termination = "no_pulling"; drive_strength_mA = < 16 >; }; // Left audio
            pin@p46 { function = "input";  termination = "no_pulling"; polarity = "active_low"; }; // Hotplug
            pin@p47 { function = "output"; termination = "pull_down"; }; // activity LED
            pin@p48 { function = "sdcard"; termination = "pull_up";    drive_strength_mA = < 8 >; }; // SD CLK
            pin@p49 { function = "sdcard"; termination = "pull_up";    drive_strength_mA = < 8 >; }; // SD CMD
            pin@p50 { function = "sdcard"; termination = "pull_up";    drive_strength_mA = < 8 >; }; // SD D0
            pin@p51 { function = "sdcard"; termination = "pull_up";    drive_strength_mA = < 8 >; }; // SD D1
            pin@p52 { function = "sdcard"; termination = "pull_up";    drive_strength_mA = < 8 >; }; // SD D2
            pin@p53 { function = "sdcard"; termination = "pull_up";    drive_strength_mA = < 8 >; }; // SD D3
         }; // pin_config

         pin_defines {
            pin_define@HDMI_CONTROL_ATTACHED {
               type = "internal";
               number = <46>;
            };
            pin_define@NUM_CAMERAS {
               type = "internal";
               number = <1>;
            };
            pin_define@CAMERA_0_I2C_PORT {
               type = "internal";
               number = <0>;
            };
            pin_define@CAMERA_0_SDA_PIN {
               type = "internal";
               number = <28>;
            };
            pin_define@CAMERA_0_SCL_PIN {
               type = "internal";
               number = <29>;
            };
            pin_define@CAMERA_0_SHUTDOWN {
               type = "internal";
               number = <41>;
            };
            pin_define@CAMERA_0_UNICAM_PORT {
               type = "internal";
               number = <1>;
            };
            pin_define@CAMERA_0_LED {
               type = "internal";
               number = <32>;
            };
            pin_define@FLASH_0_ENABLE {
               type = "absent";
            };
            pin_define@FLASH_0_INDICATOR {
               type = "absent";
            };
            pin_define@FLASH_1_ENABLE {
               type = "absent";
            };
            pin_define@FLASH_1_INDICATOR {
               type = "absent";
            };
            pin_define@POWER_LOW {
               type = "internal";
               number = <35>;
            };
            pin_define@LEDS_DISK_ACTIVITY {
               type = "internal";
               number = <47>;
            };
            pin_define@LAN_RUN {
               type = "internal";
               number = <31>;
            };
            pin_define@SMPS_SDA {
               type = "internal";
               number = <43>;
            };
            pin_define@SMPS_SCL {
               type = "internal";
               number = <42>;
            };
            pin_define@ETH_CLK {
               type = "internal";
               number = <44>;
            };
            pin_define@USB_LIMIT_1A2 {
               type = "internal";
               number = <38>;
            };
            pin_define@SIO_1V8_SEL {
               type = "absent";
            };
            pin_define@PWML {
               type = "internal";
               number = <45>;
            };
            pin_define@PWMR {
               type = "internal";
               number = <40>;
            };
            pin_define@SAFE_MODE {
               type = "internal";
               number = <3>;
            };
            pin_define@SD_CARD_DETECT {
               type = "absent";
            };
            pin_define@ID_SDA {
               type = "internal";
               number = <0>;
            };
            pin_define@ID_SCL {
               type = "internal";
               number = <1>;
            };
            pin_define@DISPLAY_I2C_PORT {
               type = "internal";
               number = <0>;
            };
            pin_define@DISPLAY_SDA {
               type = "internal";
               number = <28>;
            };
            pin_define@DISPLAY_SCL {
               type = "internal";
               number = <29>;
            };
         }; // pin_defines
      }; // pins

      pins_3b1 { // Pi 3 Model B rev 1.0
         pin_config {
            pin@default {
               polarity = "active_high";
               termination = "pull_down";
               startup_state = "inactive";
               function = "input";
            }; // pin
            // GPIOCONFIG: configure GPIO for 24-bit DPI interface
            pin@p0 { function = "dpi";  termination = "no_pulling"; drive_strength_mA = < 8 >; }; // CLK
            pin@p1 { function = "dpi";  termination = "no_pulling"; drive_strength_mA = < 8 >; }; // DEN
            pin@p2 { function = "dpi";  termination = "no_pulling"; drive_strength_mA = < 8 >; }; // VSYNC
            pin@p3 { function = "dpi";  termination = "no_pulling"; drive_strength_mA = < 8 >; }; // HSYNC
            pin@p4 { function = "dpi";  termination = "no_pulling"; drive_strength_mA = < 8 >; }; // B0
            pin@p5 { function = "dpi";  termination = "no_pulling"; drive_strength_mA = < 8 >; }; // B1
            pin@p6 { function = "dpi";  termination = "no_pulling"; drive_strength_mA = < 8 >; }; // B2
            pin@p7 { function = "dpi";  termination = "no_pulling"; drive_strength_mA = < 8 >; }; // B3
            pin@p8 { function = "dpi";  termination = "no_pulling"; drive_strength_mA = < 8 >; }; // B4
            pin@p9 { function = "dpi";  termination = "no_pulling"; drive_strength_mA = < 8 >; }; // B5
            pin@p10 { function = "dpi";  termination = "no_pulling"; drive_strength_mA = < 8 >; }; // B6
            pin@p11 { function = "dpi";  termination = "no_pulling"; drive_strength_mA = < 8 >; }; // B7
            pin@p12 { function = "dpi";  termination = "no_pulling"; drive_strength_mA = < 8 >; }; // G0
            pin@p13 { function = "dpi";  termination = "no_pulling"; drive_strength_mA = < 8 >; }; // G1
            pin@p14 { function = "dpi";  termination = "no_pulling"; drive_strength_mA = < 8 >; }; // G2
            pin@p15 { function = "dpi";  termination = "no_pulling"; drive_strength_mA = < 8 >; }; // G3
            pin@p16 { function = "dpi";  termination = "no_pulling"; drive_strength_mA = < 8 >; }; // G4
            pin@p17 { function = "dpi";  termination = "no_pulling"; drive_strength_mA = < 8 >; }; // G5
            pin@p18 { function = "dpi";  termination = "no_pulling"; drive_strength_mA = < 8 >; }; // G6
            pin@p19 { function = "dpi";  termination = "no_pulling"; drive_strength_mA = < 8 >; }; // G7
            pin@p20 { function = "dpi";  termination = "no_pulling"; drive_strength_mA = < 8 >; }; // R0
            pin@p21 { function = "dpi";  termination = "no_pulling"; drive_strength_mA = < 8 >; }; // R1
            pin@p22 { function = "dpi";  termination = "no_pulling"; drive_strength_mA = < 8 >; }; // R2
            pin@p23 { function = "dpi";  termination = "no_pulling"; drive_strength_mA = < 8 >; }; // R3
            pin@p24 { function = "dpi";  termination = "no_pulling"; drive_strength_mA = < 8 >; }; // R4
            pin@p25 { function = "dpi";  termination = "no_pulling"; drive_strength_mA = < 8 >; }; // R5
            pin@p26 { function = "dpi";  termination = "no_pulling"; drive_strength_mA = < 8 >; }; // R6
            pin@p27 { function = "dpi";  termination = "no_pulling"; drive_strength_mA = < 8 >; }; // R7
            // end GPIOCONFIG; leave the rest untouched!

	    //pin@p14 { function = "uart0";  termination = "no_pulling"; drive_strength_mA = < 8 >; }; // TX uart0
            //pin@p15 { function = "uart0";  termination = "pull_up"; drive_strength_mA = < 8 >; }; // RX uart0
            pin@p40 { function = "pwm";    termination = "no_pulling"; drive_strength_mA = < 16 >; }; // Right audio
            pin@p41 { function = "pwm";    termination = "no_pulling"; drive_strength_mA = < 16 >; }; // Left audio
            pin@p42 { function = "gp_clk"; termination = "pull_down"; }; // ETH_CLK - Ethernet 25MHz output
            pin@p43 { function = "gp_clk"; termination = "pull_down"; }; // WIFI_CLK - Wifi 32kHz output
            pin@p44 { function = "i2c0";   termination = "pull_up";    }; // I2C 0 SDA
            pin@p45 { function = "i2c0";   termination = "pull_up";    }; // I2C 0 SCL
            pin@p47 { function = "output"; termination = "pull_down"; }; // activity LED
            pin@p48 { function = "sdcard"; termination = "pull_up";    drive_strength_mA = < 8 >; }; // SD CLK
            pin@p49 { function = "sdcard"; termination = "pull_up";    drive_strength_mA = < 8 >; }; // SD CMD
            pin@p50 { function = "sdcard"; termination = "pull_up";    drive_strength_mA = < 8 >; }; // SD D0
            pin@p51 { function = "sdcard"; termination = "pull_up";    drive_strength_mA = < 8 >; }; // SD D1
            pin@p52 { function = "sdcard"; termination = "pull_up";    drive_strength_mA = < 8 >; }; // SD D2
            pin@p53 { function = "sdcard"; termination = "pull_up";    drive_strength_mA = < 8 >; }; // SD D3
            pin@p128 { function = "output"; termination = "no_pulling"; }; // BT_ON
            pin@p129 { function = "output"; termination = "no_pulling"; }; // WL_ON
            pin@p130 { function = "output"; termination = "no_pulling"; }; // Status LED
            pin@p131 { function = "output"; termination = "no_pulling"; }; // LAN_RUN
            pin@p132 { function = "input";  termination = "no_pulling"; polarity = "active_low"; }; // Hotplug
            pin@p133 { function = "output"; termination = "no_pulling"; }; // Camera LED
            pin@p134 { function = "output"; termination = "no_pulling"; }; // Camera shutdown
            pin@p135 { function = "input";  termination = "no_pulling"; polarity = "active_low"; }; // Power low
         }; // pin_config

         pin_defines {
            pin_define@HDMI_CONTROL_ATTACHED {
               type = "external";
               number = <4>;
            };
            pin_define@NUM_CAMERAS {
               type = "internal";
               number = <1>;
            };
            pin_define@CAMERA_0_I2C_PORT {
               type = "internal";
               number = <0>;
            };
            pin_define@CAMERA_0_SDA_PIN {
               type = "internal";
               number = <44>;
            };
            pin_define@CAMERA_0_SCL_PIN {
               type = "internal";
               number = <45>;
            };
            pin_define@CAMERA_0_SHUTDOWN {
               type = "external";
               number = <6>;
            };
            pin_define@CAMERA_0_UNICAM_PORT {
               type = "internal";
               number = <1>;
            };
            pin_define@CAMERA_0_LED {
               type = "external";
               number = <5>;
            };
            pin_define@FLASH_0_ENABLE {
               type = "absent";
            };
            pin_define@FLASH_0_INDICATOR {
               type = "absent";
            };
            pin_define@FLASH_1_ENABLE {
               type = "absent";
            };
            pin_define@FLASH_1_INDICATOR {
               type = "absent";
            };
            pin_define@POWER_LOW {
               type = "external";
               number = <7>;
            };
            pin_define@LEDS_DISK_ACTIVITY {
               type = "internal";
               number = <47>;
            };
            pin_define@LAN_RUN {
               type = "external";
               number = <3>;
            };
            pin_define@SMPS_SDA {
               type = "internal";
               number = <44>;
            };
            pin_define@SMPS_SCL {
               type = "internal";
               number = <45>;
            };
            pin_define@ETH_CLK {
               type = "internal";
               number = <42>;
            };
            pin_define@WL_LPO_CLK {
               type = "internal";
               number = <43>;
            };
            pin_define@USB_LIMIT_1A2 {
               type = "absent";
            };
            pin_define@SIO_1V8_SEL {
               type = "absent";
            };
            pin_define@PWML {
               type = "internal";
               number = <41>;
            };
            pin_define@PWMR {
               type = "internal";
               number = <40>;
            };
            pin_define@SAFE_MODE {
               type = "absent";
            };
            pin_define@SD_CARD_DETECT {
               type = "absent";
            };
            pin_define@ID_SDA {
               type = "internal";
               number = <0>;
            };
            pin_define@ID_SCL {
               type = "internal";
               number = <1>;
            };
            pin_define@DISPLAY_I2C_PORT {
               type = "internal";
               number = <0>;
            };
            pin_define@DISPLAY_SDA {
               type = "internal";
               number = <44>;
            };
            pin_define@DISPLAY_SCL {
               type = "internal";
               number = <45>;
            };
         }; // pin_defines
      }; // pins

      pins_3b2 { // Pi 3 Model B rev 1.2
         pin_config {
            pin@default {
               polarity = "active_high";
               termination = "pull_down";
               startup_state = "inactive";
               function = "input";
            }; // pin
            // GPIOCONFIG: configure GPIO for 24-bit DPI interface
            pin@p0 { function = "dpi";  termination = "no_pulling"; drive_strength_mA = < 8 >; }; // CLK
            pin@p1 { function = "dpi";  termination = "no_pulling"; drive_strength_mA = < 8 >; }; // DEN
            pin@p2 { function = "dpi";  termination = "no_pulling"; drive_strength_mA = < 8 >; }; // VSYNC
            pin@p3 { function = "dpi";  termination = "no_pulling"; drive_strength_mA = < 8 >; }; // HSYNC
            pin@p4 { function = "dpi";  termination = "no_pulling"; drive_strength_mA = < 8 >; }; // B0
            pin@p5 { function = "dpi";  termination = "no_pulling"; drive_strength_mA = < 8 >; }; // B1
            pin@p6 { function = "dpi";  termination = "no_pulling"; drive_strength_mA = < 8 >; }; // B2
            pin@p7 { function = "dpi";  termination = "no_pulling"; drive_strength_mA = < 8 >; }; // B3
            pin@p8 { function = "dpi";  termination = "no_pulling"; drive_strength_mA = < 8 >; }; // B4
            pin@p9 { function = "dpi";  termination = "no_pulling"; drive_strength_mA = < 8 >; }; // B5
            pin@p10 { function = "dpi";  termination = "no_pulling"; drive_strength_mA = < 8 >; }; // B6
            pin@p11 { function = "dpi";  termination = "no_pulling"; drive_strength_mA = < 8 >; }; // B7
            pin@p12 { function = "dpi";  termination = "no_pulling"; drive_strength_mA = < 8 >; }; // G0
            pin@p13 { function = "dpi";  termination = "no_pulling"; drive_strength_mA = < 8 >; }; // G1
            pin@p14 { function = "dpi";  termination = "no_pulling"; drive_strength_mA = < 8 >; }; // G2
            pin@p15 { function = "dpi";  termination = "no_pulling"; drive_strength_mA = < 8 >; }; // G3
            pin@p16 { function = "dpi";  termination = "no_pulling"; drive_strength_mA = < 8 >; }; // G4
            pin@p17 { function = "dpi";  termination = "no_pulling"; drive_strength_mA = < 8 >; }; // G5
            pin@p18 { function = "dpi";  termination = "no_pulling"; drive_strength_mA = < 8 >; }; // G6
            pin@p19 { function = "dpi";  termination = "no_pulling"; drive_strength_mA = < 8 >; }; // G7
            pin@p20 { function = "dpi";  termination = "no_pulling"; drive_strength_mA = < 8 >; }; // R0
            pin@p21 { function = "dpi";  termination = "no_pulling"; drive_strength_mA = < 8 >; }; // R1
            pin@p22 { function = "dpi";  termination = "no_pulling"; drive_strength_mA = < 8 >; }; // R2
            pin@p23 { function = "dpi";  termination = "no_pulling"; drive_strength_mA = < 8 >; }; // R3
            pin@p24 { function = "dpi";  termination = "no_pulling"; drive_strength_mA = < 8 >; }; // R4
            pin@p25 { function = "dpi";  termination = "no_pulling"; drive_strength_mA = < 8 >; }; // R5
            pin@p26 { function = "dpi";  termination = "no_pulling"; drive_strength_mA = < 8 >; }; // R6
            pin@p27 { function = "dpi";  termination = "no_pulling"; drive_strength_mA = < 8 >; }; // R7
            // end GPIOCONFIG; leave the rest untouched!

	    //pin@p14 { function = "uart0";  termination = "no_pulling"; drive_strength_mA = < 8 >; }; // TX uart0
            //pin@p15 { function = "uart0";  termination = "pull_up"; drive_strength_mA = < 8 >; }; // RX uart0
            pin@p40 { function = "pwm";    termination = "no_pulling"; drive_strength_mA = < 16 >; }; // Right audio
            pin@p41 { function = "pwm";    termination = "no_pulling"; drive_strength_mA = < 16 >; }; // Left audio
            pin@p42 { function = "gp_clk"; termination = "pull_down"; }; // ETH_CLK - Ethernet 25MHz output
            pin@p43 { function = "gp_clk"; termination = "pull_down"; }; // WIFI_CLK - Wifi 32kHz output
            pin@p44 { function = "input";   termination = "pull_up";    }; // I2C 0 SDA
            pin@p45 { function = "input";   termination = "pull_up";    }; // I2C 0 SCL
            pin@p46 { function = "input";   termination = "pull_up";    }; // SMPS_SCL
            pin@p47 { function = "input";   termination = "pull_up";    }; // SMPS_SDA
            pin@p48 { function = "sdcard"; termination = "pull_up";    drive_strength_mA = < 8 >; }; // SD CLK
            pin@p49 { function = "sdcard"; termination = "pull_up";    drive_strength_mA = < 8 >; }; // SD CMD
            pin@p50 { function = "sdcard"; termination = "pull_up";    drive_strength_mA = < 8 >; }; // SD D0
            pin@p51 { function = "sdcard"; termination = "pull_up";    drive_strength_mA = < 8 >; }; // SD D1
            pin@p52 { function = "sdcard"; termination = "pull_up";    drive_strength_mA = < 8 >; }; // SD D2
            pin@p53 { function = "sdcard"; termination = "pull_up";    drive_strength_mA = < 8 >; }; // SD D3
            pin@p128 { function = "output"; termination = "no_pulling"; }; // BT_ON
            pin@p129 { function = "output"; termination = "no_pulling"; }; // WL_ON
            pin@p130 { function = "output"; termination = "no_pulling"; }; // ACT_LED
            pin@p131 { function = "output"; termination = "no_pulling"; }; // LAN_RUN
            pin@p132 { function = "input";  termination = "no_pulling"; polarity = "active_low"; }; // Hotplug
            pin@p133 { function = "output"; termination = "no_pulling"; }; // Camera LED
            pin@p134 { function = "output"; termination = "no_pulling"; }; // Camera shutdown
            pin@p135 { function = "input";  termination = "no_pulling"; polarity = "active_low"; }; // Power low
         }; // pin_config

         pin_defines {
            pin_define@HDMI_CONTROL_ATTACHED {
               type = "external";
               number = <4>;
            };
            pin_define@NUM_CAMERAS {
               type = "internal";
               number = <1>;
            };
            pin_define@CAMERA_0_I2C_PORT {
               type = "internal";
               number = <0>;
            };
            pin_define@CAMERA_0_SDA_PIN {
               type = "internal";
               number = <44>;
            };
            pin_define@CAMERA_0_SCL_PIN {
               type = "internal";
               number = <45>;
            };
            pin_define@CAMERA_0_SHUTDOWN {
               type = "external";
               number = <5>;
            };
            pin_define@CAMERA_0_UNICAM_PORT {
               type = "internal";
               number = <1>;
            };
            pin_define@CAMERA_0_LED {
               type = "external";
               number = <6>;
            };
            pin_define@FLASH_0_ENABLE {
               type = "absent";
            };
            pin_define@FLASH_0_INDICATOR {
               type = "absent";
            };
            pin_define@FLASH_1_ENABLE {
               type = "absent";
            };
            pin_define@FLASH_1_INDICATOR {
               type = "absent";
            };
            pin_define@POWER_LOW {
               type = "external";
               number = <7>;
            };
            pin_define@LEDS_DISK_ACTIVITY {
               type = "external";
               number = <2>;
            };
            pin_define@LAN_RUN {
               type = "external";
               number = <3>;
            };
            pin_define@SMPS_SDA {
               type = "internal";
               number = <46>;
            };
            pin_define@SMPS_SCL {
               type = "internal";
               number = <47>;
            };
            pin_define@ETH_CLK {
               type = "internal";
               number = <42>;
            };
            pin_define@WL_LPO_CLK {
               type = "internal";
               number = <43>;
            };
            pin_define@USB_LIMIT_1A2 {
               type = "absent";
            };
            pin_define@SIO_1V8_SEL {
               type = "absent";
            };
            pin_define@PWML {
               type = "internal";
               number = <41>;
            };
            pin_define@PWMR {
               type = "internal";
               number = <40>;
            };
            pin_define@SAFE_MODE {
               type = "absent";
            };
            pin_define@SD_CARD_DETECT {
               type = "absent";
            };
            pin_define@ID_SDA {
               type = "internal";
               number = <0>;
            };
            pin_define@ID_SCL {
               type = "internal";
               number = <1>;
            };
            pin_define@DISPLAY_I2C_PORT {
               type = "internal";
               number = <0>;
            };
            pin_define@DISPLAY_SDA {
               type = "internal";
               number = <44>;
            };
            pin_define@DISPLAY_SCL {
               type = "internal";
               number = <45>;
            };
         }; // pin_defines
      }; // pins

      pins_cm3 { // Pi 3 CM3
         pin_config {
            pin@default {
               polarity = "active_high";
               termination = "pull_down";
               startup_state = "inactive";
               function = "input";
            }; // pin
            pin@p14 { function = "uart0";  termination = "no_pulling"; drive_strength_mA = < 8 >; }; // TX uart0
            pin@p15 { function = "uart0";  termination = "pull_up"; drive_strength_mA = < 8 >; }; // RX uart0
            pin@p46 { function = "input";   termination = "pull_up";    }; // SMPS_SCL
            pin@p47 { function = "input";   termination = "pull_up";    }; // SMPS_SDA
            pin@p48 { function = "sdcard"; termination = "pull_up";    drive_strength_mA = < 8 >; }; // SD CLK
            pin@p49 { function = "sdcard"; termination = "pull_up";    drive_strength_mA = < 8 >; }; // SD CMD
            pin@p50 { function = "sdcard"; termination = "pull_up";    drive_strength_mA = < 8 >; }; // SD D0
            pin@p51 { function = "sdcard"; termination = "pull_up";    drive_strength_mA = < 8 >; }; // SD D1
            pin@p52 { function = "sdcard"; termination = "pull_up";    drive_strength_mA = < 8 >; }; // SD D2
            pin@p53 { function = "sdcard"; termination = "pull_up";    drive_strength_mA = < 8 >; }; // SD D3
            pin@p128 { function = "input";  termination = "no_pulling"; polarity = "active_low"; }; // Hotplug
            pin@p129 { function = "output"; termination = "no_pulling"; polarity = "active_low"; }; // EMMC_ENABLE_N
         }; // pin_config

         pin_defines {
            pin_define@HDMI_CONTROL_ATTACHED {
               type = "external";
               number = <0>;
            };
            pin_define@EMMC_ENABLE {
               type = "external";
               number = <1>;
            };
            pin_define@NUM_CAMERAS {
               type = "internal";
               number = <0>;
            };
            pin_define@POWER_LOW {
               type = "absent";
            };
            pin_define@LEDS_DISK_ACTIVITY {
               type = "absent";
            };
            pin_define@LAN_RUN {
               type = "absent";
            };
            pin_define@SMPS_SDA {
               type = "internal";
               number = <46>;
            };
            pin_define@SMPS_SCL {
               type = "internal";
               number = <47>;
            };
            pin_define@ETH_CLK {
               type = "absent";
            };
            pin_define@WL_LPO_CLK {
               type = "absent";
            };
            pin_define@USB_LIMIT_1A2 {
               type = "absent";
            };
            pin_define@SIO_1V8_SEL {
               type = "absent";
            };
            pin_define@PWML {
               type = "absent";
            };
            pin_define@PWMR {
               type = "absent";
            };
            pin_define@SAFE_MODE {
               type = "absent";
            };
            pin_define@SD_CARD_DETECT {
               type = "absent";
            };
            pin_define@ID_SDA {
               type = "absent";
            };
            pin_define@ID_SCL {
               type = "absent";
            };
         }; // pin_defines
      }; // pins

      pins_pi0 { // Pi zero
         pin_config {
            pin@default {
               polarity = "active_high";
               termination = "pull_down";
               startup_state = "inactive";
               function = "input";
            }; // pin
            // GPIOCONFIG: configure GPIO for 24-bit DPI interface
            pin@p0 { function = "dpi";  termination = "no_pulling"; drive_strength_mA = < 8 >; }; // CLK
            pin@p1 { function = "dpi";  termination = "no_pulling"; drive_strength_mA = < 8 >; }; // DEN
            pin@p2 { function = "dpi";  termination = "no_pulling"; drive_strength_mA = < 8 >; }; // VSYNC
            pin@p3 { function = "dpi";  termination = "no_pulling"; drive_strength_mA = < 8 >; }; // HSYNC
            pin@p4 { function = "dpi";  termination = "no_pulling"; drive_strength_mA = < 8 >; }; // B0
            pin@p5 { function = "dpi";  termination = "no_pulling"; drive_strength_mA = < 8 >; }; // B1
            pin@p6 { function = "dpi";  termination = "no_pulling"; drive_strength_mA = < 8 >; }; // B2
            pin@p7 { function = "dpi";  termination = "no_pulling"; drive_strength_mA = < 8 >; }; // B3
            pin@p8 { function = "dpi";  termination = "no_pulling"; drive_strength_mA = < 8 >; }; // B4
            pin@p9 { function = "dpi";  termination = "no_pulling"; drive_strength_mA = < 8 >; }; // B5
            pin@p10 { function = "dpi";  termination = "no_pulling"; drive_strength_mA = < 8 >; }; // B6
            pin@p11 { function = "dpi";  termination = "no_pulling"; drive_strength_mA = < 8 >; }; // B7
            pin@p12 { function = "dpi";  termination = "no_pulling"; drive_strength_mA = < 8 >; }; // G0
            pin@p13 { function = "dpi";  termination = "no_pulling"; drive_strength_mA = < 8 >; }; // G1
            pin@p14 { function = "dpi";  termination = "no_pulling"; drive_strength_mA = < 8 >; }; // G2
            pin@p15 { function = "dpi";  termination = "no_pulling"; drive_strength_mA = < 8 >; }; // G3
            pin@p16 { function = "dpi";  termination = "no_pulling"; drive_strength_mA = < 8 >; }; // G4
            pin@p17 { function = "dpi";  termination = "no_pulling"; drive_strength_mA = < 8 >; }; // G5
            pin@p18 { function = "dpi";  termination = "no_pulling"; drive_strength_mA = < 8 >; }; // G6
            pin@p19 { function = "dpi";  termination = "no_pulling"; drive_strength_mA = < 8 >; }; // G7

            pin@p20 { function = "input";   termination = "pull_up";    };  //Up
            pin@p21 { function = "input";   termination = "pull_up";    };  //Down
            pin@p22 { function = "input";   termination = "pull_up";    };  //Left
            pin@p23 { function = "input";   termination = "pull_up";    };  //Right
            pin@p24 { function = "input";   termination = "pull_up";    };  //Select
            pin@p25 { function = "input";   termination = "pull_up";    };  //Start
            pin@p26 { function = "input";   termination = "pull_up";    };  //B
            pin@p27 { function = "input";   termination = "pull_up";    };  //A
            // end GPIOCONFIG; leave the rest untouched!

	    //pin@p14 { function = "uart0";  termination = "no_pulling"; drive_strength_mA = < 8 >; }; // TX uart0
            //pin@p15 { function = "uart0";  termination = "pull_up"; drive_strength_mA = < 8 >; }; // RX uart0
            pin@p46 { function = "input";  termination = "no_pulling"; polarity = "active_low"; }; // Hotplug
            pin@p47 { function = "output"; termination = "pull_up"; polarity="active_low"; }; // activity LED
            pin@p48 { function = "sdcard"; termination = "pull_up";    drive_strength_mA = < 8 >; }; // SD CLK
            pin@p49 { function = "sdcard"; termination = "pull_up";    drive_strength_mA = < 8 >; }; // SD CMD
            pin@p50 { function = "sdcard"; termination = "pull_up";    drive_strength_mA = < 8 >; }; // SD D0
            pin@p51 { function = "sdcard"; termination = "pull_up";    drive_strength_mA = < 8 >; }; // SD D1
            pin@p52 { function = "sdcard"; termination = "pull_up";    drive_strength_mA = < 8 >; }; // SD D2
            pin@p53 { function = "sdcard"; termination = "pull_up";    drive_strength_mA = < 8 >; }; // SD D3
         }; // pin_config

         pin_defines {
            pin_define@HDMI_CONTROL_ATTACHED {
               type = "internal";
               number = <46>;
            };
            pin_define@NUM_CAMERAS {
               type = "internal";
               number = <0>;
            };
            pin_define@CAMERA_0_I2C_PORT {
               type = "absent";
            };
            pin_define@CAMERA_0_SDA_PIN {
               type = "absent";
            };
            pin_define@CAMERA_0_SCL_PIN {
               type = "absent";
            };
            pin_define@CAMERA_0_SHUTDOWN {
               type = "absent";
            };
            pin_define@CAMERA_0_UNICAM_PORT {
               type = "absent";
            };
            pin_define@CAMERA_0_LED {
               type = "absent";
            };
            pin_define@FLASH_0_ENABLE {
               type = "absent";
            };
            pin_define@FLASH_0_INDICATOR {
               type = "absent";
            };
            pin_define@FLASH_1_ENABLE {
               type = "absent";
            };
            pin_define@FLASH_1_INDICATOR {
               type = "absent";
            };
            pin_define@POWER_LOW {
               type = "absent";
            };
            pin_define@LEDS_DISK_ACTIVITY {
               type = "internal";
               number = <47>;
            };
            pin_define@LAN_RUN {
               type = "absent";
            };
            pin_define@SMPS_SDA {
               type = "absent";
            };
            pin_define@SMPS_SCL {
               type = "absent";
            };
            pin_define@ETH_CLK {
               type = "absent";
            };
            pin_define@USB_LIMIT_1A2 {
               type = "absent";
            };
            pin_define@SIO_1V8_SEL {
               type = "absent";
            };
            pin_define@PWML {
               type = "absent";
            };
            pin_define@PWMR {
               type = "absent";
            };
            pin_define@SAFE_MODE {
               type = "absent";
            };
            pin_define@SD_CARD_DETECT {
               type = "absent";
            };
            pin_define@ID_SDA {
               type = "internal";
               number = <0>;
            };
            pin_define@ID_SCL {
               type = "internal";
               number = <1>;
            };
            pin_define@DISPLAY_I2C_PORT {
               type = "absent";
            };
            pin_define@DISPLAY_SDA {
               type = "absent";
            };
            pin_define@DISPLAY_SCL {
               type = "absent";
            };
         }; // pin_defines
      }; // pins

      pins_cm {
         pin_config {
            pin@default {
               polarity = "active_high";
               termination = "pull_down";
               startup_state = "inactive";
               function = "input";
            }; // pin
            pin@p14 { function = "uart0";  termination = "no_pulling"; }; // TX uart0
            pin@p15 { function = "uart0";  termination = "pull_up"; }; // RX uart0
            pin@p47 { function = "output"; termination = "no_pulling"; polarity = "active_low"; }; // EMMC_ENABLE_N
            pin@p48 { function = "sdcard"; termination = "pull_up";    drive_strength_mA = < 8 >; }; // SD CLK
            pin@p49 { function = "sdcard"; termination = "pull_up";    drive_strength_mA = < 8 >; }; // SD CMD
            pin@p50 { function = "sdcard"; termination = "pull_up";    drive_strength_mA = < 8 >; }; // SD D0
            pin@p51 { function = "sdcard"; termination = "pull_up";    drive_strength_mA = < 8 >; }; // SD D1
            pin@p52 { function = "sdcard"; termination = "pull_up";    drive_strength_mA = < 8 >; }; // SD D2
            pin@p53 { function = "sdcard"; termination = "pull_up";    drive_strength_mA = < 8 >; }; // SD D3
         }; // pin_config

         pin_defines {
            pin_define@EMMC_ENABLE {
               type = "internal";
               number = <47>;
            };
         }; // pin_defines
      }; // pins_cm
   };
};
